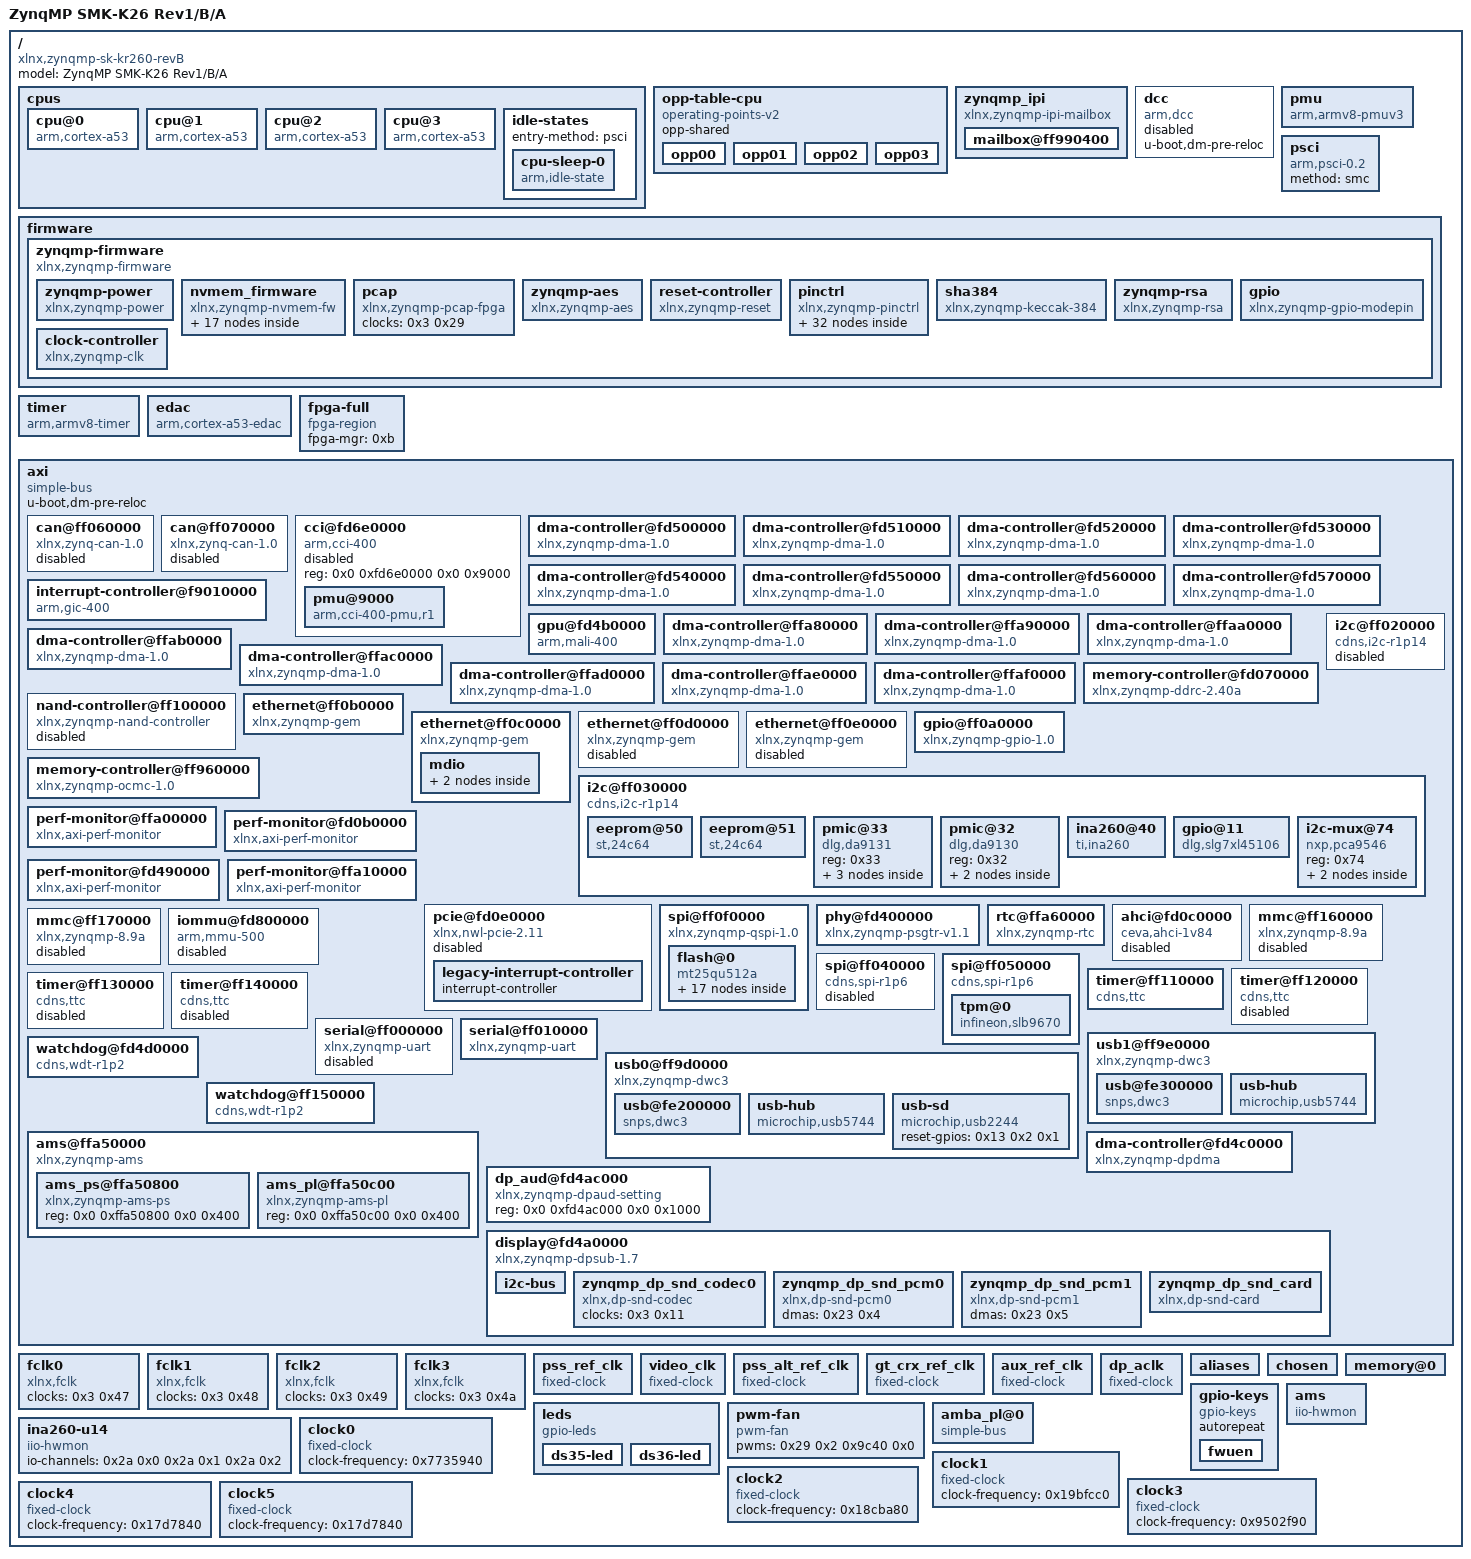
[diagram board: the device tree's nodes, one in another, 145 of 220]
/dts-v1/;

/ {
	compatible = "xlnx,zynqmp-sk-kr260-revB", "xlnx,zynqmp-sk-kr260", "xlnx,zynqmp";
	#address-cells = <0x2>;
	#size-cells = <0x2>;
	model = "ZynqMP SMK-K26 Rev1/B/A";

	cpus {
		#address-cells = <0x1>;
		#size-cells = <0x0>;

		cpu@0 {
			compatible = "arm,cortex-a53";
			device_type = "cpu";
			enable-method = "psci";
			operating-points-v2 = <0x1>;
			reg = <0x0>;
			cpu-idle-states = <0x2>;
			clocks = <0x3 0xa>;
			phandle = <0x2b>;
		};

		cpu@1 {
			compatible = "arm,cortex-a53";
			device_type = "cpu";
			enable-method = "psci";
			reg = <0x1>;
			operating-points-v2 = <0x1>;
			cpu-idle-states = <0x2>;
			phandle = <0x2c>;
		};

		cpu@2 {
			compatible = "arm,cortex-a53";
			device_type = "cpu";
			enable-method = "psci";
			reg = <0x2>;
			operating-points-v2 = <0x1>;
			cpu-idle-states = <0x2>;
			phandle = <0x2d>;
		};

		cpu@3 {
			compatible = "arm,cortex-a53";
			device_type = "cpu";
			enable-method = "psci";
			reg = <0x3>;
			operating-points-v2 = <0x1>;
			cpu-idle-states = <0x2>;
			phandle = <0x2e>;
		};

		idle-states {
			entry-method = "psci";

			cpu-sleep-0 {
				compatible = "arm,idle-state";
				arm,psci-suspend-param = <0x40000000>;
				local-timer-stop;
				entry-latency-us = <0x12c>;
				exit-latency-us = <0x258>;
				min-residency-us = <0x2710>;
				phandle = <0x2>;
			};
		};
	};

	opp-table-cpu {
		compatible = "operating-points-v2";
		opp-shared;
		phandle = <0x1>;

		opp00 {
			opp-hz = <0x0 0x4f790d55>;
			opp-microvolt = <0xf4240>;
			clock-latency-ns = <0x7a120>;
		};

		opp01 {
			opp-hz = <0x0 0x27bc86aa>;
			opp-microvolt = <0xf4240>;
			clock-latency-ns = <0x7a120>;
		};

		opp02 {
			opp-hz = <0x0 0x1a7daf1c>;
			opp-microvolt = <0xf4240>;
			clock-latency-ns = <0x7a120>;
		};

		opp03 {
			opp-hz = <0x0 0x13de4355>;
			opp-microvolt = <0xf4240>;
			clock-latency-ns = <0x7a120>;
		};
	};

	zynqmp_ipi {
		u-boot,dm-pre-reloc;
		compatible = "xlnx,zynqmp-ipi-mailbox";
		interrupt-parent = <0x4>;
		interrupts = <0x0 0x23 0x4>;
		xlnx,ipi-id = <0x0>;
		#address-cells = <0x2>;
		#size-cells = <0x2>;
		ranges;
		phandle = <0x2f>;

		mailbox@ff990400 {
			u-boot,dm-pre-reloc;
			reg = <0x0 0xff9905c0 0x0 0x20 0x0 0xff9905e0 0x0 0x20 0x0 0xff990e80 0x0 0x20 0x0 0xff990ea0 0x0 0x20>;
			reg-names = "local_request_region", "local_response_region", "remote_request_region", "remote_response_region";
			#mbox-cells = <0x1>;
			xlnx,ipi-id = <0x4>;
			phandle = <0x5>;
		};
	};

	dcc {
		compatible = "arm,dcc";
		status = "disabled";
		u-boot,dm-pre-reloc;
		phandle = <0x30>;
	};

	pmu {
		compatible = "arm,armv8-pmuv3";
		interrupt-parent = <0x4>;
		interrupts = <0x0 0x8f 0x4 0x0 0x90 0x4 0x0 0x91 0x4 0x0 0x92 0x4>;
	};

	psci {
		compatible = "arm,psci-0.2";
		method = "smc";
	};

	firmware {

		zynqmp-firmware {
			compatible = "xlnx,zynqmp-firmware";
			#power-domain-cells = <0x1>;
			method = "smc";
			u-boot,dm-pre-reloc;
			phandle = <0xc>;

			zynqmp-power {
				u-boot,dm-pre-reloc;
				compatible = "xlnx,zynqmp-power";
				interrupt-parent = <0x4>;
				interrupts = <0x0 0x23 0x4>;
				mboxes = <0x5 0x0 0x5 0x1>;
				mbox-names = "tx", "rx";
				phandle = <0x31>;
			};

			nvmem_firmware {
				compatible = "xlnx,zynqmp-nvmem-fw";
				#address-cells = <0x1>;
				#size-cells = <0x1>;

				soc_revision@0 {
					reg = <0x0 0x4>;
					phandle = <0x32>;
				};

				efuse_dna@c {
					reg = <0xc 0xc>;
					phandle = <0x33>;
				};

				efuse_usr0@20 {
					reg = <0x20 0x4>;
					phandle = <0x34>;
				};

				efuse_usr1@24 {
					reg = <0x24 0x4>;
					phandle = <0x35>;
				};

				efuse_usr2@28 {
					reg = <0x28 0x4>;
					phandle = <0x36>;
				};

				efuse_usr3@2c {
					reg = <0x2c 0x4>;
					phandle = <0x37>;
				};

				efuse_usr4@30 {
					reg = <0x30 0x4>;
					phandle = <0x38>;
				};

				efuse_usr5@34 {
					reg = <0x34 0x4>;
					phandle = <0x39>;
				};

				efuse_usr6@38 {
					reg = <0x38 0x4>;
					phandle = <0x3a>;
				};

				efuse_usr7@3c {
					reg = <0x3c 0x4>;
					phandle = <0x3b>;
				};

				efuse_miscusr@40 {
					reg = <0x40 0x4>;
					phandle = <0x3c>;
				};

				efuse_chash@50 {
					reg = <0x50 0x4>;
					phandle = <0x3d>;
				};

				efuse_pufmisc@54 {
					reg = <0x54 0x4>;
					phandle = <0x3e>;
				};

				efuse_sec@58 {
					reg = <0x58 0x4>;
					phandle = <0x3f>;
				};

				efuse_spkid@5c {
					reg = <0x5c 0x4>;
					phandle = <0x40>;
				};

				efuse_ppk0hash@a0 {
					reg = <0xa0 0x30>;
					phandle = <0x41>;
				};

				efuse_ppk1hash@d0 {
					reg = <0xd0 0x30>;
					phandle = <0x42>;
				};
			};

			pcap {
				compatible = "xlnx,zynqmp-pcap-fpga";
				clock-names = "ref_clk";
				clocks = <0x3 0x29>;
				phandle = <0xb>;
			};

			zynqmp-aes {
				compatible = "xlnx,zynqmp-aes";
				phandle = <0x43>;
			};

			reset-controller {
				compatible = "xlnx,zynqmp-reset";
				#reset-cells = <0x1>;
				phandle = <0xe>;
			};

			pinctrl {
				compatible = "xlnx,zynqmp-pinctrl";
				status = "okay";
				phandle = <0x44>;

				sdhci0-default {
					phandle = <0x1c>;

					conf {
						groups = "sdio0_0_grp";
						slew-rate = <0x1>;
						power-source = <0x1>;
						bias-disable;
					};

					mux {
						groups = "sdio0_0_grp";
						function = "sdio0";
					};
				};

				uart1-default {
					phandle = <0x1d>;

					conf {
						groups = "uart1_9_grp";
						slew-rate = <0x1>;
						power-source = <0x1>;
						drive-strength = <0xc>;
					};

					conf-rx {
						pins = "MIO37";
						bias-high-impedance;
					};

					conf-tx {
						pins = "MIO36";
						bias-disable;
					};

					mux {
						groups = "uart1_9_grp";
						function = "uart1";
					};
				};

				i2c1-default {
					phandle = <0x15>;

					conf {
						groups = "i2c1_6_grp";
						bias-pull-up;
						slew-rate = <0x1>;
						power-source = <0x1>;
					};

					mux {
						groups = "i2c1_6_grp";
						function = "i2c1";
					};
				};

				i2c1-gpio {
					phandle = <0x16>;

					conf {
						groups = "gpio0_24_grp", "gpio0_25_grp";
						slew-rate = <0x1>;
						power-source = <0x1>;
					};

					mux {
						groups = "gpio0_24_grp", "gpio0_25_grp";
						function = "gpio0";
					};
				};

				gem1-default {
					phandle = <0x11>;

					conf {
						groups = "ethernet1_0_grp";
						slew-rate = <0x1>;
						power-source = <0x1>;
					};

					conf-rx {
						pins = "MIO44", "MIO46", "MIO48";
						bias-high-impedance;
						low-power-disable;
					};

					conf-bootstrap {
						pins = "MIO45", "MIO47", "MIO49";
						bias-disable;
						low-power-disable;
					};

					conf-tx {
						pins = "MIO38", "MIO39", "MIO40", "MIO41", "MIO42", "MIO43";
						bias-disable;
						low-power-enable;
					};

					conf-mdio {
						groups = "mdio1_0_grp";
						slew-rate = <0x1>;
						power-source = <0x1>;
						bias-disable;
					};

					mux-mdio {
						function = "mdio1";
						groups = "mdio1_0_grp";
					};

					mux {
						function = "ethernet1";
						groups = "ethernet1_0_grp";
					};
				};

				usb0-default {
					phandle = <0x1e>;

					conf {
						groups = "usb0_0_grp";
						power-source = <0x1>;
					};

					conf-rx {
						pins = "MIO52", "MIO53", "MIO55";
						bias-high-impedance;
						drive-strength = <0xc>;
						slew-rate = <0x0>;
					};

					conf-tx {
						pins = "MIO54", "MIO56", "MIO57", "MIO58", "MIO59", "MIO60", "MIO61", "MIO62", "MIO63";
						bias-disable;
						drive-strength = <0x4>;
						slew-rate = <0x1>;
					};

					mux {
						groups = "usb0_0_grp";
						function = "usb0";
					};
				};

				usb1-default {
					phandle = <0x20>;

					conf {
						groups = "usb1_0_grp";
						power-source = <0x1>;
					};

					conf-rx {
						pins = "MIO64", "MIO65", "MIO67";
						bias-high-impedance;
						drive-strength = <0xc>;
						slew-rate = <0x0>;
					};

					conf-tx {
						pins = "MIO66", "MIO68", "MIO69", "MIO70", "MIO71", "MIO72", "MIO73", "MIO74", "MIO75";
						bias-disable;
						drive-strength = <0x4>;
						slew-rate = <0x1>;
					};

					mux {
						groups = "usb1_0_grp";
						function = "usb1";
					};
				};
			};

			sha384 {
				compatible = "xlnx,zynqmp-keccak-384";
				phandle = <0x45>;
			};

			zynqmp-rsa {
				compatible = "xlnx,zynqmp-rsa";
				phandle = <0x46>;
			};

			gpio {
				compatible = "xlnx,zynqmp-gpio-modepin";
				gpio-controller;
				#gpio-cells = <0x2>;
				label = "modepin";
				phandle = <0x47>;
			};

			clock-controller {
				u-boot,dm-pre-reloc;
				#clock-cells = <0x1>;
				compatible = "xlnx,zynqmp-clk";
				clocks = <0x6 0x7 0x8 0x9 0xa>;
				clock-names = "pss_ref_clk", "video_clk", "pss_alt_ref_clk", "aux_ref_clk", "gt_crx_ref_clk";
				phandle = <0x3>;
			};
		};
	};

	timer {
		compatible = "arm,armv8-timer";
		interrupt-parent = <0x4>;
		interrupts = <0x1 0xd 0xf08 0x1 0xe 0xf08 0x1 0xb 0xf08 0x1 0xa 0xf08>;
	};

	edac {
		compatible = "arm,cortex-a53-edac";
	};

	fpga-full {
		compatible = "fpga-region";
		fpga-mgr = <0xb>;
		#address-cells = <0x2>;
		#size-cells = <0x2>;
		ranges;
		phandle = <0x48>;
	};

	axi {
		compatible = "simple-bus";
		u-boot,dm-pre-reloc;
		#address-cells = <0x2>;
		#size-cells = <0x2>;
		ranges;
		phandle = <0x49>;

		can@ff060000 {
			compatible = "xlnx,zynq-can-1.0";
			status = "disabled";
			clock-names = "can_clk", "pclk";
			reg = <0x0 0xff060000 0x0 0x1000>;
			interrupts = <0x0 0x17 0x4>;
			interrupt-parent = <0x4>;
			tx-fifo-depth = <0x40>;
			rx-fifo-depth = <0x40>;
			power-domains = <0xc 0x2f>;
			clocks = <0x3 0x3f 0x3 0x1f>;
			phandle = <0x4a>;
		};

		can@ff070000 {
			compatible = "xlnx,zynq-can-1.0";
			status = "disabled";
			clock-names = "can_clk", "pclk";
			reg = <0x0 0xff070000 0x0 0x1000>;
			interrupts = <0x0 0x18 0x4>;
			interrupt-parent = <0x4>;
			tx-fifo-depth = <0x40>;
			rx-fifo-depth = <0x40>;
			power-domains = <0xc 0x30>;
			clocks = <0x3 0x40 0x3 0x1f>;
			phandle = <0x4b>;
		};

		cci@fd6e0000 {
			compatible = "arm,cci-400";
			status = "disabled";
			reg = <0x0 0xfd6e0000 0x0 0x9000>;
			ranges = <0x0 0x0 0xfd6e0000 0x10000>;
			#address-cells = <0x1>;
			#size-cells = <0x1>;
			phandle = <0x4c>;

			pmu@9000 {
				compatible = "arm,cci-400-pmu,r1";
				reg = <0x9000 0x5000>;
				interrupt-parent = <0x4>;
				interrupts = <0x0 0x7b 0x4 0x0 0x7b 0x4 0x0 0x7b 0x4 0x0 0x7b 0x4 0x0 0x7b 0x4>;
			};
		};

		dma-controller@fd500000 {
			status = "okay";
			compatible = "xlnx,zynqmp-dma-1.0";
			reg = <0x0 0xfd500000 0x0 0x1000>;
			interrupt-parent = <0x4>;
			interrupts = <0x0 0x7c 0x4>;
			clock-names = "clk_main", "clk_apb";
			xlnx,bus-width = <0x80>;
			iommus = <0xd 0x14e8>;
			power-domains = <0xc 0x2a>;
			#dma-cells = <0x1>;
			clocks = <0x3 0x13 0x3 0x1f>;
			phandle = <0x4d>;
		};

		dma-controller@fd510000 {
			status = "okay";
			compatible = "xlnx,zynqmp-dma-1.0";
			reg = <0x0 0xfd510000 0x0 0x1000>;
			interrupt-parent = <0x4>;
			interrupts = <0x0 0x7d 0x4>;
			clock-names = "clk_main", "clk_apb";
			xlnx,bus-width = <0x80>;
			iommus = <0xd 0x14e9>;
			power-domains = <0xc 0x2a>;
			#dma-cells = <0x1>;
			clocks = <0x3 0x13 0x3 0x1f>;
			phandle = <0x4e>;
		};

		dma-controller@fd520000 {
			status = "okay";
			compatible = "xlnx,zynqmp-dma-1.0";
			reg = <0x0 0xfd520000 0x0 0x1000>;
			interrupt-parent = <0x4>;
			interrupts = <0x0 0x7e 0x4>;
			clock-names = "clk_main", "clk_apb";
			xlnx,bus-width = <0x80>;
			iommus = <0xd 0x14ea>;
			power-domains = <0xc 0x2a>;
			#dma-cells = <0x1>;
			clocks = <0x3 0x13 0x3 0x1f>;
			phandle = <0x4f>;
		};

		dma-controller@fd530000 {
			status = "okay";
			compatible = "xlnx,zynqmp-dma-1.0";
			reg = <0x0 0xfd530000 0x0 0x1000>;
			interrupt-parent = <0x4>;
			interrupts = <0x0 0x7f 0x4>;
			clock-names = "clk_main", "clk_apb";
			xlnx,bus-width = <0x80>;
			iommus = <0xd 0x14eb>;
			power-domains = <0xc 0x2a>;
			#dma-cells = <0x1>;
			clocks = <0x3 0x13 0x3 0x1f>;
			phandle = <0x50>;
		};

		dma-controller@fd540000 {
			status = "okay";
			compatible = "xlnx,zynqmp-dma-1.0";
			reg = <0x0 0xfd540000 0x0 0x1000>;
			interrupt-parent = <0x4>;
			interrupts = <0x0 0x80 0x4>;
			clock-names = "clk_main", "clk_apb";
			xlnx,bus-width = <0x80>;
			iommus = <0xd 0x14ec>;
			power-domains = <0xc 0x2a>;
			#dma-cells = <0x1>;
			clocks = <0x3 0x13 0x3 0x1f>;
			phandle = <0x51>;
		};

		dma-controller@fd550000 {
			status = "okay";
			compatible = "xlnx,zynqmp-dma-1.0";
			reg = <0x0 0xfd550000 0x0 0x1000>;
			interrupt-parent = <0x4>;
			interrupts = <0x0 0x81 0x4>;
			clock-names = "clk_main", "clk_apb";
			xlnx,bus-width = <0x80>;
			iommus = <0xd 0x14ed>;
			power-domains = <0xc 0x2a>;
			#dma-cells = <0x1>;
			clocks = <0x3 0x13 0x3 0x1f>;
			phandle = <0x52>;
		};

		dma-controller@fd560000 {
			status = "okay";
			compatible = "xlnx,zynqmp-dma-1.0";
			reg = <0x0 0xfd560000 0x0 0x1000>;
			interrupt-parent = <0x4>;
			interrupts = <0x0 0x82 0x4>;
			clock-names = "clk_main", "clk_apb";
			xlnx,bus-width = <0x80>;
			iommus = <0xd 0x14ee>;
			power-domains = <0xc 0x2a>;
			#dma-cells = <0x1>;
			clocks = <0x3 0x13 0x3 0x1f>;
			phandle = <0x53>;
		};

		dma-controller@fd570000 {
			status = "okay";
			compatible = "xlnx,zynqmp-dma-1.0";
			reg = <0x0 0xfd570000 0x0 0x1000>;
			interrupt-parent = <0x4>;
			interrupts = <0x0 0x83 0x4>;
			clock-names = "clk_main", "clk_apb";
			xlnx,bus-width = <0x80>;
			iommus = <0xd 0x14ef>;
			power-domains = <0xc 0x2a>;
			#dma-cells = <0x1>;
			clocks = <0x3 0x13 0x3 0x1f>;
			phandle = <0x54>;
		};

		interrupt-controller@f9010000 {
			compatible = "arm,gic-400";
			#interrupt-cells = <0x3>;
			reg = <0x0 0xf9010000 0x0 0x10000 0x0 0xf9020000 0x0 0x20000 0x0 0xf9040000 0x0 0x20000 0x0 0xf9060000 0x0 0x20000>;
			interrupt-controller;
			interrupt-parent = <0x4>;
			interrupts = <0x1 0x9 0xf04>;
			phandle = <0x4>;
		};

		gpu@fd4b0000 {
			status = "okay";
			compatible = "arm,mali-400", "arm,mali-utgard";
			reg = <0x0 0xfd4b0000 0x0 0x10000>;
			interrupt-parent = <0x4>;
			interrupts = <0x0 0x84 0x4 0x0 0x84 0x4 0x0 0x84 0x4 0x0 0x84 0x4 0x0 0x84 0x4 0x0 0x84 0x4>;
			interrupt-names = "IRQGP", "IRQGPMMU", "IRQPP0", "IRQPPMMU0", "IRQPP1", "IRQPPMMU1";
			clock-names = "gpu", "gpu_pp0", "gpu_pp1";
			power-domains = <0xc 0x3a>;
			clocks = <0x3 0x18 0x3 0x19 0x3 0x1a>;
			phandle = <0x55>;
		};

		dma-controller@ffa80000 {
			status = "okay";
			compatible = "xlnx,zynqmp-dma-1.0";
			reg = <0x0 0xffa80000 0x0 0x1000>;
			interrupt-parent = <0x4>;
			interrupts = <0x0 0x4d 0x4>;
			clock-names = "clk_main", "clk_apb";
			xlnx,bus-width = <0x40>;
			power-domains = <0xc 0x2b>;
			#dma-cells = <0x1>;
			clocks = <0x3 0x44 0x3 0x1f>;
			phandle = <0x56>;
		};

		dma-controller@ffa90000 {
			status = "okay";
			compatible = "xlnx,zynqmp-dma-1.0";
			reg = <0x0 0xffa90000 0x0 0x1000>;
			interrupt-parent = <0x4>;
			interrupts = <0x0 0x4e 0x4>;
			clock-names = "clk_main", "clk_apb";
			xlnx,bus-width = <0x40>;
			power-domains = <0xc 0x2b>;
			#dma-cells = <0x1>;
			clocks = <0x3 0x44 0x3 0x1f>;
			phandle = <0x57>;
		};

		dma-controller@ffaa0000 {
			status = "okay";
			compatible = "xlnx,zynqmp-dma-1.0";
			reg = <0x0 0xffaa0000 0x0 0x1000>;
			interrupt-parent = <0x4>;
			interrupts = <0x0 0x4f 0x4>;
			clock-names = "clk_main", "clk_apb";
			xlnx,bus-width = <0x40>;
			power-domains = <0xc 0x2b>;
			#dma-cells = <0x1>;
			clocks = <0x3 0x44 0x3 0x1f>;
			phandle = <0x58>;
		};

		dma-controller@ffab0000 {
			status = "okay";
			compatible = "xlnx,zynqmp-dma-1.0";
			reg = <0x0 0xffab0000 0x0 0x1000>;
			interrupt-parent = <0x4>;
			interrupts = <0x0 0x50 0x4>;
			clock-names = "clk_main", "clk_apb";
			xlnx,bus-width = <0x40>;
			power-domains = <0xc 0x2b>;
			#dma-cells = <0x1>;
			clocks = <0x3 0x44 0x3 0x1f>;
			phandle = <0x59>;
		};

		dma-controller@ffac0000 {
			status = "okay";
			compatible = "xlnx,zynqmp-dma-1.0";
			reg = <0x0 0xffac0000 0x0 0x1000>;
			interrupt-parent = <0x4>;
			interrupts = <0x0 0x51 0x4>;
			clock-names = "clk_main", "clk_apb";
			xlnx,bus-width = <0x40>;
			power-domains = <0xc 0x2b>;
			#dma-cells = <0x1>;
			clocks = <0x3 0x44 0x3 0x1f>;
			phandle = <0x5a>;
		};

		dma-controller@ffad0000 {
			status = "okay";
			compatible = "xlnx,zynqmp-dma-1.0";
			reg = <0x0 0xffad0000 0x0 0x1000>;
			interrupt-parent = <0x4>;
			interrupts = <0x0 0x52 0x4>;
			clock-names = "clk_main", "clk_apb";
			xlnx,bus-width = <0x40>;
			power-domains = <0xc 0x2b>;
			#dma-cells = <0x1>;
			clocks = <0x3 0x44 0x3 0x1f>;
			phandle = <0x5b>;
		};

		dma-controller@ffae0000 {
			status = "okay";
			compatible = "xlnx,zynqmp-dma-1.0";
			reg = <0x0 0xffae0000 0x0 0x1000>;
			interrupt-parent = <0x4>;
			interrupts = <0x0 0x53 0x4>;
			clock-names = "clk_main", "clk_apb";
			xlnx,bus-width = <0x40>;
			power-domains = <0xc 0x2b>;
			#dma-cells = <0x1>;
			clocks = <0x3 0x44 0x3 0x1f>;
			phandle = <0x5c>;
		};

		dma-controller@ffaf0000 {
			status = "okay";
			compatible = "xlnx,zynqmp-dma-1.0";
			reg = <0x0 0xffaf0000 0x0 0x1000>;
			interrupt-parent = <0x4>;
			interrupts = <0x0 0x54 0x4>;
			clock-names = "clk_main", "clk_apb";
			xlnx,bus-width = <0x40>;
			power-domains = <0xc 0x2b>;
			#dma-cells = <0x1>;
			clocks = <0x3 0x44 0x3 0x1f>;
			phandle = <0x5d>;
		};

		memory-controller@fd070000 {
			compatible = "xlnx,zynqmp-ddrc-2.40a";
			reg = <0x0 0xfd070000 0x0 0x30000>;
			interrupt-parent = <0x4>;
			interrupts = <0x0 0x70 0x4>;
			phandle = <0x5e>;
		};

		nand-controller@ff100000 {
			compatible = "xlnx,zynqmp-nand-controller", "arasan,nfc-v3p10";
			status = "disabled";
			reg = <0x0 0xff100000 0x0 0x1000>;
			clock-names = "controller", "bus";
			interrupt-parent = <0x4>;
			interrupts = <0x0 0xe 0x4>;
			#address-cells = <0x1>;
			#size-cells = <0x0>;
			iommus = <0xd 0x872>;
			power-domains = <0xc 0x2c>;
			clocks = <0x3 0x3c 0x3 0x1f>;
			phandle = <0x5f>;
		};

		ethernet@ff0b0000 {
			compatible = "xlnx,zynqmp-gem", "cdns,zynqmp-gem", "cdns,gem";
			status = "okay";
			interrupt-parent = <0x4>;
			interrupts = <0x0 0x39 0x4 0x0 0x39 0x4>;
			reg = <0x0 0xff0b0000 0x0 0x1000>;
			clock-names = "pclk", "hclk", "tx_clk", "rx_clk", "tsu_clk";
			#address-cells = <0x1>;
			#size-cells = <0x0>;
			iommus = <0xd 0x874>;
			power-domains = <0xc 0x1d>;
			resets = <0xe 0x1d>;
			clocks = <0x3 0x1f 0x3 0x68 0x3 0x2d 0x3 0x31 0x3 0x2c>;
			phys = <0xf 0x0 0x8 0x0 0x0>;
			phy-handle = <0x10>;
			phy-mode = "sgmii";
			is-internal-pcspma;
			phandle = <0x60>;
		};

		ethernet@ff0c0000 {
			compatible = "xlnx,zynqmp-gem", "cdns,zynqmp-gem", "cdns,gem";
			status = "okay";
			interrupt-parent = <0x4>;
			interrupts = <0x0 0x3b 0x4 0x0 0x3b 0x4>;
			reg = <0x0 0xff0c0000 0x0 0x1000>;
			clock-names = "pclk", "hclk", "tx_clk", "rx_clk", "tsu_clk";
			#address-cells = <0x1>;
			#size-cells = <0x0>;
			iommus = <0xd 0x875>;
			power-domains = <0xc 0x1e>;
			resets = <0xe 0x1e>;
			clocks = <0x3 0x1f 0x3 0x69 0x3 0x2e 0x3 0x32 0x3 0x2c>;
			pinctrl-names = "default";
			pinctrl-0 = <0x11>;
			phy-handle = <0x12>;
			phy-mode = "rgmii-id";
			phandle = <0x61>;

			mdio {
				#address-cells = <0x1>;
				#size-cells = <0x0>;
				phandle = <0x62>;

				ethernet-phy@4 {
					#phy-cells = <0x1>;
					compatible = "ethernet-phy-id2000.a231";
					reg = <0x4>;
					ti,rx-internal-delay = <0x8>;
					ti,tx-internal-delay = <0xa>;
					ti,fifo-depth = <0x1>;
					ti,dp83867-rxctrl-strap-quirk;
					reset-assert-us = <0x64>;
					reset-deassert-us = <0x118>;
					reset-gpios = <0x13 0x5 0x1>;
					phandle = <0x10>;
				};

				ethernet-phy@8 {
					#phy-cells = <0x1>;
					compatible = "ethernet-phy-id2000.a231";
					reg = <0x8>;
					ti,rx-internal-delay = <0x8>;
					ti,tx-internal-delay = <0xa>;
					ti,fifo-depth = <0x1>;
					ti,dp83867-rxctrl-strap-quirk;
					reset-assert-us = <0x64>;
					reset-deassert-us = <0x118>;
					reset-gpios = <0x13 0x6 0x1>;
					phandle = <0x12>;
				};
			};
		};

		ethernet@ff0d0000 {
			compatible = "xlnx,zynqmp-gem", "cdns,zynqmp-gem", "cdns,gem";
			status = "disabled";
			interrupt-parent = <0x4>;
			interrupts = <0x0 0x3d 0x4 0x0 0x3d 0x4>;
			reg = <0x0 0xff0d0000 0x0 0x1000>;
			clock-names = "pclk", "hclk", "tx_clk", "rx_clk", "tsu_clk";
			#address-cells = <0x1>;
			#size-cells = <0x0>;
			iommus = <0xd 0x876>;
			power-domains = <0xc 0x1f>;
			resets = <0xe 0x1f>;
			clocks = <0x3 0x1f 0x3 0x6a 0x3 0x2f 0x3 0x33 0x3 0x2c>;
			phandle = <0x63>;
		};

		ethernet@ff0e0000 {
			compatible = "xlnx,zynqmp-gem", "cdns,zynqmp-gem", "cdns,gem";
			status = "disabled";
			interrupt-parent = <0x4>;
			interrupts = <0x0 0x3f 0x4 0x0 0x3f 0x4>;
			reg = <0x0 0xff0e0000 0x0 0x1000>;
			clock-names = "pclk", "hclk", "tx_clk", "rx_clk", "tsu_clk";
			#address-cells = <0x1>;
			#size-cells = <0x0>;
			iommus = <0xd 0x877>;
			power-domains = <0xc 0x20>;
			resets = <0xe 0x20>;
			clocks = <0x3 0x1f 0x3 0x6b 0x3 0x30 0x3 0x34 0x3 0x2c>;
			phandle = <0x64>;
		};

		gpio@ff0a0000 {
			compatible = "xlnx,zynqmp-gpio-1.0";
			status = "okay";
			#gpio-cells = <0x2>;
			gpio-controller;
			interrupt-parent = <0x4>;
			interrupts = <0x0 0x10 0x4>;
			interrupt-controller;
			#interrupt-cells = <0x2>;
			reg = <0x0 0xff0a0000 0x0 0x1000>;
			power-domains = <0xc 0x2e>;
			clocks = <0x3 0x1f>;
			gpio-line-names = "QSPI_CLK", "QSPI_DQ1", "QSPI_DQ2", "QSPI_DQ3", "QSPI_DQ0", "QSPI_CS_B", "SPI_CLK", "LED1", "LED2", "SPI_CS_B", "SPI_MISO", "SPI_MOSI", "FWUEN", "EMMC_DAT0", "EMMC_DAT1", "EMMC_DAT2", "EMMC_DAT3", "EMMC_DAT4", "EMMC_DAT5", "EMMC_DAT6", "EMMC_DAT7", "EMMC_CMD", "EMMC_CLK", "EMMC_RST", "I2C1_SCL", "I2C1_SDA", "", "", "", "", "", "", "", "", "", "", "", "", "", "", "", "", "", "", "", "", "", "", "", "", "", "", "", "", "", "", "", "", "", "", "", "", "", "", "", "", "", "", "", "", "", "", "", "", "", "", "", "", "", "", "", "", "", "", "", "", "", "", "", "", "", "", "", "", "", "", "", "", "", "", "", "", "", "", "", "", "", "", "", "", "", "", "", "", "", "", "", "", "", "", "", "", "", "", "", "", "", "", "", "", "", "", "", "", "", "", "", "", "", "", "", "", "", "", "", "", "", "", "", "", "", "", "", "", "", "", "", "", "", "", "", "", "", "", "", "", "", "", "", "", "", "", "", "";
			phandle = <0x14>;
		};

		i2c@ff020000 {
			compatible = "cdns,i2c-r1p14";
			status = "disabled";
			interrupt-parent = <0x4>;
			interrupts = <0x0 0x11 0x4>;
			reg = <0x0 0xff020000 0x0 0x1000>;
			#address-cells = <0x1>;
			#size-cells = <0x0>;
			power-domains = <0xc 0x25>;
			clocks = <0x3 0x3d>;
			phandle = <0x65>;
		};

		i2c@ff030000 {
			compatible = "cdns,i2c-r1p14";
			status = "okay";
			interrupt-parent = <0x4>;
			interrupts = <0x0 0x12 0x4>;
			reg = <0x0 0xff030000 0x0 0x1000>;
			#address-cells = <0x1>;
			#size-cells = <0x0>;
			power-domains = <0xc 0x26>;
			clocks = <0x3 0x3e>;
			u-boot,dm-pre-reloc;
			clock-frequency = <0x61a80>;
			scl-gpios = <0x14 0x18 0x0>;
			sda-gpios = <0x14 0x19 0x0>;
			pinctrl-names = "default", "gpio";
			pinctrl-0 = <0x15>;
			pinctrl-1 = <0x16>;
			phandle = <0x66>;

			eeprom@50 {
				u-boot,dm-pre-reloc;
				compatible = "st,24c64", "atmel,24c64";
				reg = <0x50>;
				phandle = <0x67>;
			};

			eeprom@51 {
				u-boot,dm-pre-reloc;
				compatible = "st,24c64", "atmel,24c64";
				reg = <0x51>;
				phandle = <0x68>;
			};

			pmic@33 {
				compatible = "dlg,da9131";
				reg = <0x33>;
				phandle = <0x69>;

				regulators {

					buck1 {
						regulator-name = "da9131_buck1";
						regulator-boot-on;
						regulator-always-on;
						phandle = <0x6a>;
					};

					buck2 {
						regulator-name = "da9131_buck2";
						regulator-boot-on;
						regulator-always-on;
						phandle = <0x6b>;
					};
				};
			};

			pmic@32 {
				compatible = "dlg,da9130";
				reg = <0x32>;
				phandle = <0x6c>;

				regulators {

					buck1 {
						regulator-name = "da9130_buck1";
						regulator-boot-on;
						regulator-always-on;
						phandle = <0x6d>;
					};
				};
			};

			ina260@40 {
				compatible = "ti,ina260";
				#io-channel-cells = <0x1>;
				label = "ina260-u14";
				reg = <0x40>;
				phandle = <0x2a>;
			};

			gpio@11 {
				compatible = "dlg,slg7xl45106";
				reg = <0x11>;
				label = "resetchip";
				gpio-controller;
				#gpio-cells = <0x2>;
				gpio-line-names = "USB0_PHY_RESET_B", "USB1_PHY_RESET_B", "SD_RESET_B", "USB0_HUB_RESET_B", "USB1_HUB_RESET_B", "PS_GEM0_RESET_B", "PS_GEM1_RESET_B", "";
				phandle = <0x13>;
			};

			i2c-mux@74 {
				compatible = "nxp,pca9546";
				#address-cells = <0x1>;
				#size-cells = <0x0>;
				reg = <0x74>;

				i2c@0 {
					#address-cells = <0x1>;
					#size-cells = <0x0>;
					reg = <0x0>;
					phandle = <0x1f>;
				};

				i2c@1 {
					#address-cells = <0x1>;
					#size-cells = <0x0>;
					reg = <0x1>;
					phandle = <0x21>;
				};
			};
		};

		memory-controller@ff960000 {
			compatible = "xlnx,zynqmp-ocmc-1.0";
			reg = <0x0 0xff960000 0x0 0x1000>;
			interrupt-parent = <0x4>;
			interrupts = <0x0 0xa 0x4>;
			phandle = <0x6e>;
		};

		perf-monitor@ffa00000 {
			compatible = "xlnx,axi-perf-monitor";
			reg = <0x0 0xffa00000 0x0 0x10000>;
			interrupts = <0x0 0x19 0x4>;
			interrupt-parent = <0x4>;
			xlnx,enable-profile = <0x0>;
			xlnx,enable-trace = <0x0>;
			xlnx,num-monitor-slots = <0x1>;
			xlnx,enable-event-count = <0x1>;
			xlnx,enable-event-log = <0x1>;
			xlnx,have-sampled-metric-cnt = <0x1>;
			xlnx,num-of-counters = <0x8>;
			xlnx,metric-count-width = <0x20>;
			xlnx,metrics-sample-count-width = <0x20>;
			xlnx,global-count-width = <0x20>;
			xlnx,metric-count-scale = <0x1>;
			clocks = <0x3 0x1f>;
			phandle = <0x6f>;
		};

		perf-monitor@fd0b0000 {
			compatible = "xlnx,axi-perf-monitor";
			reg = <0x0 0xfd0b0000 0x0 0x10000>;
			interrupts = <0x0 0x7b 0x4>;
			interrupt-parent = <0x4>;
			xlnx,enable-profile = <0x0>;
			xlnx,enable-trace = <0x0>;
			xlnx,num-monitor-slots = <0x6>;
			xlnx,enable-event-count = <0x1>;
			xlnx,enable-event-log = <0x0>;
			xlnx,have-sampled-metric-cnt = <0x1>;
			xlnx,num-of-counters = <0xa>;
			xlnx,metric-count-width = <0x20>;
			xlnx,metrics-sample-count-width = <0x20>;
			xlnx,global-count-width = <0x20>;
			xlnx,metric-count-scale = <0x1>;
			clocks = <0x3 0x1c>;
			phandle = <0x70>;
		};

		perf-monitor@fd490000 {
			compatible = "xlnx,axi-perf-monitor";
			reg = <0x0 0xfd490000 0x0 0x10000>;
			interrupts = <0x0 0x7b 0x4>;
			interrupt-parent = <0x4>;
			xlnx,enable-profile = <0x0>;
			xlnx,enable-trace = <0x0>;
			xlnx,num-monitor-slots = <0x1>;
			xlnx,enable-event-count = <0x1>;
			xlnx,enable-event-log = <0x0>;
			xlnx,have-sampled-metric-cnt = <0x1>;
			xlnx,num-of-counters = <0x8>;
			xlnx,metric-count-width = <0x20>;
			xlnx,metrics-sample-count-width = <0x20>;
			xlnx,global-count-width = <0x20>;
			xlnx,metric-count-scale = <0x1>;
			clocks = <0x3 0x1c>;
			phandle = <0x71>;
		};

		perf-monitor@ffa10000 {
			compatible = "xlnx,axi-perf-monitor";
			reg = <0x0 0xffa10000 0x0 0x10000>;
			interrupts = <0x0 0x19 0x4>;
			interrupt-parent = <0x4>;
			xlnx,enable-profile = <0x0>;
			xlnx,enable-trace = <0x0>;
			xlnx,num-monitor-slots = <0x1>;
			xlnx,enable-event-count = <0x1>;
			xlnx,enable-event-log = <0x1>;
			xlnx,have-sampled-metric-cnt = <0x1>;
			xlnx,num-of-counters = <0x8>;
			xlnx,metric-count-width = <0x20>;
			xlnx,metrics-sample-count-width = <0x20>;
			xlnx,global-count-width = <0x20>;
			xlnx,metric-count-scale = <0x1>;
			clocks = <0x3 0x1f>;
			phandle = <0x72>;
		};

		pcie@fd0e0000 {
			compatible = "xlnx,nwl-pcie-2.11";
			status = "disabled";
			#address-cells = <0x3>;
			#size-cells = <0x2>;
			#interrupt-cells = <0x1>;
			msi-controller;
			device_type = "pci";
			interrupt-parent = <0x4>;
			interrupts = <0x0 0x76 0x4 0x0 0x75 0x4 0x0 0x74 0x4 0x0 0x73 0x4 0x0 0x72 0x4>;
			interrupt-names = "misc", "dummy", "intx", "msi1", "msi0";
			msi-parent = <0x17>;
			reg = <0x0 0xfd0e0000 0x0 0x1000 0x0 0xfd480000 0x0 0x1000 0x80 0x0 0x0 0x1000000>;
			reg-names = "breg", "pcireg", "cfg";
			ranges = <0x2000000 0x0 0xe0000000 0x0 0xe0000000 0x0 0x10000000 0x43000000 0x6 0x0 0x6 0x0 0x2 0x0>;
			bus-range = <0x0 0xff>;
			interrupt-map-mask = <0x0 0x0 0x0 0x7>;
			interrupt-map = <0x0 0x0 0x0 0x1 0x18 0x1 0x0 0x0 0x0 0x2 0x18 0x2 0x0 0x0 0x0 0x3 0x18 0x3 0x0 0x0 0x0 0x4 0x18 0x4>;
			iommus = <0xd 0x4d0>;
			power-domains = <0xc 0x3b>;
			clocks = <0x3 0x17>;
			phandle = <0x17>;

			legacy-interrupt-controller {
				interrupt-controller;
				#address-cells = <0x0>;
				#interrupt-cells = <0x1>;
				phandle = <0x18>;
			};
		};

		spi@ff0f0000 {
			u-boot,dm-pre-reloc;
			compatible = "xlnx,zynqmp-qspi-1.0";
			status = "okay";
			clock-names = "ref_clk", "pclk";
			interrupts = <0x0 0xf 0x4>;
			interrupt-parent = <0x4>;
			num-cs = <0x1>;
			reg = <0x0 0xff0f0000 0x0 0x1000 0x0 0xc0000000 0x0 0x8000000>;
			#address-cells = <0x1>;
			#size-cells = <0x0>;
			iommus = <0xd 0x873>;
			power-domains = <0xc 0x2d>;
			clocks = <0x3 0x35 0x3 0x1f>;
			phandle = <0x73>;

			flash@0 {
				compatible = "mt25qu512a", "jedec,spi-nor";
				#address-cells = <0x1>;
				#size-cells = <0x1>;
				reg = <0x0>;
				spi-tx-bus-width = <0x4>;
				spi-rx-bus-width = <0x4>;
				spi-max-frequency = <0x2625a00>;

				partition@0 {
					label = "Image Selector";
					reg = <0x0 0x80000>;
					read-only;
					lock;
				};

				partition@80000 {
					label = "Image Selector Golden";
					reg = <0x80000 0x80000>;
					read-only;
					lock;
				};

				partition@100000 {
					label = "Persistent Register";
					reg = <0x100000 0x20000>;
				};

				partition@120000 {
					label = "Persistent Register Backup";
					reg = <0x120000 0x20000>;
				};

				partition@140000 {
					label = "Open_1";
					reg = <0x140000 0xc0000>;
				};

				partition@200000 {
					label = "Image A (FSBL, PMU, ATF, U-Boot)";
					reg = <0x200000 0xd00000>;
				};

				partition@f00000 {
					label = "ImgSel Image A Catch";
					reg = <0xf00000 0x80000>;
					read-only;
					lock;
				};

				partition@f80000 {
					label = "Image B (FSBL, PMU, ATF, U-Boot)";
					reg = <0xf80000 0xd00000>;
				};

				partition@1c80000 {
					label = "ImgSel Image B Catch";
					reg = <0x1c80000 0x80000>;
					read-only;
					lock;
				};

				partition@1d00000 {
					label = "Open_2";
					reg = <0x1d00000 0x100000>;
				};

				partition@1e00000 {
					label = "Recovery Image";
					reg = <0x1e00000 0x200000>;
					read-only;
					lock;
				};

				partition@2000000 {
					label = "Recovery Image Backup";
					reg = <0x2000000 0x200000>;
					read-only;
					lock;
				};

				partition@2200000 {
					label = "U-Boot storage variables";
					reg = <0x2200000 0x20000>;
				};

				partition@2220000 {
					label = "U-Boot storage variables backup";
					reg = <0x2220000 0x20000>;
				};

				partition@2240000 {
					label = "SHA256";
					reg = <0x2240000 0x40000>;
					read-only;
					lock;
				};

				partition@2280000 {
					label = "Secure OS Storage";
					reg = <0x2280000 0x20000>;
				};

				partition@22A0000 {
					label = "User";
					reg = <0x22a0000 0x1db0000>;
				};
			};
		};

		phy@fd400000 {
			compatible = "xlnx,zynqmp-psgtr-v1.1";
			status = "okay";
			reg = <0x0 0xfd400000 0x0 0x40000 0x0 0xfd3d0000 0x0 0x1000>;
			reg-names = "serdes", "siou";
			#phy-cells = <0x4>;
			clocks = <0x19 0x1a 0x1b>;
			clock-names = "ref0", "ref1", "ref2";
			phandle = <0xf>;
		};

		rtc@ffa60000 {
			compatible = "xlnx,zynqmp-rtc";
			status = "okay";
			reg = <0x0 0xffa60000 0x0 0x100>;
			interrupt-parent = <0x4>;
			interrupts = <0x0 0x1a 0x4 0x0 0x1b 0x4>;
			interrupt-names = "alarm", "sec";
			calibration = <0x7fff>;
			phandle = <0x74>;
		};

		ahci@fd0c0000 {
			compatible = "ceva,ahci-1v84";
			status = "disabled";
			reg = <0x0 0xfd0c0000 0x0 0x2000>;
			interrupt-parent = <0x4>;
			interrupts = <0x0 0x85 0x4>;
			power-domains = <0xc 0x1c>;
			resets = <0xe 0x10>;
			clocks = <0x3 0x16>;
			phandle = <0x75>;
		};

		mmc@ff160000 {
			u-boot,dm-pre-reloc;
			compatible = "xlnx,zynqmp-8.9a", "arasan,sdhci-8.9a";
			status = "disabled";
			interrupt-parent = <0x4>;
			interrupts = <0x0 0x30 0x4>;
			reg = <0x0 0xff160000 0x0 0x1000>;
			clock-names = "clk_xin", "clk_ahb";
			xlnx,device_id = <0x0>;
			iommus = <0xd 0x870>;
			#clock-cells = <0x1>;
			clock-output-names = "clk_out_sd0", "clk_in_sd0";
			power-domains = <0xc 0x27>;
			resets = <0xe 0x26>;
			clocks = <0x3 0x36 0x3 0x1f>;
			assigned-clocks = <0x3 0x36>;
			pinctrl-names = "default";
			pinctrl-0 = <0x1c>;
			non-removable;
			disable-wp;
			bus-width = <0x8>;
			xlnx,mio-bank = <0x0>;
			assigned-clock-rates = <0xb2cfe8b>;
			phandle = <0x76>;
		};

		mmc@ff170000 {
			u-boot,dm-pre-reloc;
			compatible = "xlnx,zynqmp-8.9a", "arasan,sdhci-8.9a";
			status = "disabled";
			interrupt-parent = <0x4>;
			interrupts = <0x0 0x31 0x4>;
			reg = <0x0 0xff170000 0x0 0x1000>;
			clock-names = "clk_xin", "clk_ahb";
			xlnx,device_id = <0x1>;
			iommus = <0xd 0x871>;
			#clock-cells = <0x1>;
			clock-output-names = "clk_out_sd1", "clk_in_sd1";
			power-domains = <0xc 0x28>;
			resets = <0xe 0x27>;
			clocks = <0x3 0x37 0x3 0x1f>;
			assigned-clocks = <0x3 0x37>;
			phandle = <0x77>;
		};

		iommu@fd800000 {
			compatible = "arm,mmu-500";
			reg = <0x0 0xfd800000 0x0 0x20000>;
			#iommu-cells = <0x1>;
			status = "disabled";
			#global-interrupts = <0x1>;
			interrupt-parent = <0x4>;
			interrupts = <0x0 0x9b 0x4 0x0 0x9b 0x4 0x0 0x9b 0x4 0x0 0x9b 0x4 0x0 0x9b 0x4 0x0 0x9b 0x4 0x0 0x9b 0x4 0x0 0x9b 0x4 0x0 0x9b 0x4 0x0 0x9b 0x4 0x0 0x9b 0x4 0x0 0x9b 0x4 0x0 0x9b 0x4 0x0 0x9b 0x4 0x0 0x9b 0x4 0x0 0x9b 0x4 0x0 0x9b 0x4>;
			phandle = <0xd>;
		};

		spi@ff040000 {
			compatible = "cdns,spi-r1p6";
			status = "disabled";
			interrupt-parent = <0x4>;
			interrupts = <0x0 0x13 0x4>;
			reg = <0x0 0xff040000 0x0 0x1000>;
			clock-names = "ref_clk", "pclk";
			#address-cells = <0x1>;
			#size-cells = <0x0>;
			power-domains = <0xc 0x23>;
			clocks = <0x3 0x3a 0x3 0x1f>;
			phandle = <0x78>;
		};

		spi@ff050000 {
			compatible = "cdns,spi-r1p6";
			status = "okay";
			interrupt-parent = <0x4>;
			interrupts = <0x0 0x14 0x4>;
			reg = <0x0 0xff050000 0x0 0x1000>;
			clock-names = "ref_clk", "pclk";
			#address-cells = <0x1>;
			#size-cells = <0x0>;
			power-domains = <0xc 0x24>;
			clocks = <0x3 0x3b 0x3 0x1f>;
			label = "TPM";
			num-cs = <0x1>;
			phandle = <0x79>;

			tpm@0 {
				compatible = "infineon,slb9670", "tcg,tpm_tis-spi";
				reg = <0x0>;
				spi-max-frequency = <0x11a49a0>;
			};
		};

		timer@ff110000 {
			compatible = "cdns,ttc";
			status = "okay";
			interrupt-parent = <0x4>;
			interrupts = <0x0 0x24 0x4 0x0 0x25 0x4 0x0 0x26 0x4>;
			reg = <0x0 0xff110000 0x0 0x1000>;
			timer-width = <0x20>;
			power-domains = <0xc 0x18>;
			clocks = <0x3 0x1f>;
			#pwm-cells = <0x3>;
			phandle = <0x29>;
		};

		timer@ff120000 {
			compatible = "cdns,ttc";
			status = "disabled";
			interrupt-parent = <0x4>;
			interrupts = <0x0 0x27 0x4 0x0 0x28 0x4 0x0 0x29 0x4>;
			reg = <0x0 0xff120000 0x0 0x1000>;
			timer-width = <0x20>;
			power-domains = <0xc 0x19>;
			clocks = <0x3 0x1f>;
			phandle = <0x7a>;
		};

		timer@ff130000 {
			compatible = "cdns,ttc";
			status = "disabled";
			interrupt-parent = <0x4>;
			interrupts = <0x0 0x2a 0x4 0x0 0x2b 0x4 0x0 0x2c 0x4>;
			reg = <0x0 0xff130000 0x0 0x1000>;
			timer-width = <0x20>;
			power-domains = <0xc 0x1a>;
			clocks = <0x3 0x1f>;
			phandle = <0x7b>;
		};

		timer@ff140000 {
			compatible = "cdns,ttc";
			status = "disabled";
			interrupt-parent = <0x4>;
			interrupts = <0x0 0x2d 0x4 0x0 0x2e 0x4 0x0 0x2f 0x4>;
			reg = <0x0 0xff140000 0x0 0x1000>;
			timer-width = <0x20>;
			power-domains = <0xc 0x1b>;
			clocks = <0x3 0x1f>;
			phandle = <0x7c>;
		};

		serial@ff000000 {
			u-boot,dm-pre-reloc;
			compatible = "xlnx,zynqmp-uart", "cdns,uart-r1p12";
			status = "disabled";
			interrupt-parent = <0x4>;
			interrupts = <0x0 0x15 0x4>;
			reg = <0x0 0xff000000 0x0 0x1000>;
			clock-names = "uart_clk", "pclk";
			power-domains = <0xc 0x21>;
			clocks = <0x3 0x38 0x3 0x1f>;
			phandle = <0x7d>;
		};

		serial@ff010000 {
			u-boot,dm-pre-reloc;
			compatible = "xlnx,zynqmp-uart", "cdns,uart-r1p12";
			status = "okay";
			interrupt-parent = <0x4>;
			interrupts = <0x0 0x16 0x4>;
			reg = <0x0 0xff010000 0x0 0x1000>;
			clock-names = "uart_clk", "pclk";
			power-domains = <0xc 0x22>;
			clocks = <0x3 0x39 0x3 0x1f>;
			pinctrl-names = "default";
			pinctrl-0 = <0x1d>;
			phandle = <0x7e>;
		};

		usb0@ff9d0000 {
			#address-cells = <0x2>;
			#size-cells = <0x2>;
			status = "okay";
			compatible = "xlnx,zynqmp-dwc3";
			reg = <0x0 0xff9d0000 0x0 0x100>;
			clock-names = "bus_clk", "ref_clk";
			power-domains = <0xc 0x16>;
			resets = <0xe 0x3b 0xe 0x3d 0xe 0x3f>;
			reset-names = "usb_crst", "usb_hibrst", "usb_apbrst";
			reset-gpios = <0x13 0x0 0x1>;
			ranges;
			clocks = <0x3 0x20 0x3 0x22>;
			assigned-clocks = <0x3 0x20 0x3 0x22>;
			pinctrl-names = "default";
			pinctrl-0 = <0x1e>;
			phy-names = "usb3-phy";
			phys = <0xf 0x2 0x4 0x0 0x2>;
			assigned-clock-rates = <0xee6b280 0x1312d00>;
			phandle = <0x7f>;

			usb@fe200000 {
				compatible = "snps,dwc3";
				status = "okay";
				reg = <0x0 0xfe200000 0x0 0x40000>;
				interrupt-parent = <0x4>;
				interrupt-names = "dwc_usb3", "otg", "hiber";
				interrupts = <0x0 0x41 0x4 0x0 0x45 0x4 0x0 0x4b 0x4>;
				iommus = <0xd 0x860>;
				snps,quirk-frame-length-adjustment = <0x20>;
				snps,refclk_fladj;
				clock-names = "ref";
				snps,enable_guctl1_resume_quirk;
				snps,enable_guctl1_ipd_quirk;
				snps,xhci-reset-on-resume;
				snps,xhci-stream-quirk;
				clocks = <0x3 0x22>;
				dr_mode = "host";
				snps,usb3_lpm_capable;
				maximum-speed = "super-speed";
				phandle = <0x80>;
			};

			usb-hub {
				i2c-bus = <0x1f>;
				compatible = "microchip,usb5744";
				reset-gpios = <0x13 0x3 0x1>;
				phandle = <0x81>;
			};

			usb-sd {
				compatible = "microchip,usb2244";
				reset-gpios = <0x13 0x2 0x1>;
				phandle = <0x82>;
			};
		};

		usb1@ff9e0000 {
			#address-cells = <0x2>;
			#size-cells = <0x2>;
			status = "okay";
			compatible = "xlnx,zynqmp-dwc3";
			reg = <0x0 0xff9e0000 0x0 0x100>;
			clock-names = "bus_clk", "ref_clk";
			power-domains = <0xc 0x17>;
			resets = <0xe 0x3c 0xe 0x3e 0xe 0x40>;
			reset-names = "usb_crst", "usb_hibrst", "usb_apbrst";
			ranges;
			clocks = <0x3 0x21 0x3 0x22>;
			assigned-clocks = <0x3 0x21 0x3 0x22>;
			pinctrl-names = "default";
			pinctrl-0 = <0x20>;
			phy-names = "usb3-phy";
			phys = <0xf 0x3 0x4 0x1 0x2>;
			reset-gpios = <0x13 0x1 0x1>;
			assigned-clock-rates = <0xee6b280 0x1312d00>;
			phandle = <0x83>;

			usb@fe300000 {
				compatible = "snps,dwc3";
				status = "okay";
				reg = <0x0 0xfe300000 0x0 0x40000>;
				interrupt-parent = <0x4>;
				interrupt-names = "dwc_usb3", "otg", "hiber";
				interrupts = <0x0 0x46 0x4 0x0 0x4a 0x4 0x0 0x4c 0x4>;
				iommus = <0xd 0x861>;
				snps,quirk-frame-length-adjustment = <0x20>;
				snps,refclk_fladj;
				clock-names = "ref";
				snps,enable_guctl1_resume_quirk;
				snps,enable_guctl1_ipd_quirk;
				snps,xhci-reset-on-resume;
				snps,xhci-stream-quirk;
				clocks = <0x3 0x22>;
				dr_mode = "host";
				snps,usb3_lpm_capable;
				maximum-speed = "super-speed";
				phandle = <0x84>;
			};

			usb-hub {
				i2c-bus = <0x21>;
				compatible = "microchip,usb5744";
				reset-gpios = <0x13 0x4 0x1>;
				phandle = <0x85>;
			};
		};

		watchdog@fd4d0000 {
			compatible = "cdns,wdt-r1p2";
			status = "okay";
			interrupt-parent = <0x4>;
			interrupts = <0x0 0x71 0x1>;
			reg = <0x0 0xfd4d0000 0x0 0x1000>;
			timeout-sec = <0x3c>;
			reset-on-timeout;
			clocks = <0x3 0x4b>;
			phandle = <0x86>;
		};

		watchdog@ff150000 {
			compatible = "cdns,wdt-r1p2";
			status = "okay";
			interrupt-parent = <0x4>;
			interrupts = <0x0 0x34 0x1>;
			reg = <0x0 0xff150000 0x0 0x1000>;
			timeout-sec = <0xa>;
			clocks = <0x3 0x70>;
			phandle = <0x87>;
		};

		ams@ffa50000 {
			compatible = "xlnx,zynqmp-ams";
			status = "okay";
			interrupt-parent = <0x4>;
			interrupts = <0x0 0x38 0x4>;
			interrupt-names = "ams-irq";
			reg = <0x0 0xffa50000 0x0 0x800>;
			reg-names = "ams-base";
			#address-cells = <0x2>;
			#size-cells = <0x2>;
			#io-channel-cells = <0x1>;
			ranges;
			clocks = <0x3 0x46>;
			phandle = <0x28>;

			ams_ps@ffa50800 {
				compatible = "xlnx,zynqmp-ams-ps";
				status = "okay";
				reg = <0x0 0xffa50800 0x0 0x400>;
				phandle = <0x88>;
			};

			ams_pl@ffa50c00 {
				compatible = "xlnx,zynqmp-ams-pl";
				status = "okay";
				reg = <0x0 0xffa50c00 0x0 0x400>;
				phandle = <0x89>;
			};
		};

		dma-controller@fd4c0000 {
			compatible = "xlnx,zynqmp-dpdma";
			status = "okay";
			reg = <0x0 0xfd4c0000 0x0 0x1000>;
			interrupts = <0x0 0x7a 0x4>;
			interrupt-parent = <0x4>;
			clock-names = "axi_clk";
			power-domains = <0xc 0x29>;
			dma-channels = <0x6>;
			iommus = <0xd 0xce4>;
			#dma-cells = <0x1>;
			clocks = <0x3 0x14>;
			assigned-clocks = <0x3 0x14>;
			assigned-clock-rates = <0x23c34600>;
			phandle = <0x23>;
		};

		dp_aud@fd4ac000 {
			compatible = "xlnx,zynqmp-dpaud-setting", "syscon";
			reg = <0x0 0xfd4ac000 0x0 0x1000>;
			phandle = <0x22>;
		};

		display@fd4a0000 {
			u-boot,dm-pre-reloc;
			compatible = "xlnx,zynqmp-dpsub-1.7";
			status = "okay";
			reg = <0x0 0xfd4a0000 0x0 0x1000 0x0 0xfd4aa000 0x0 0x1000 0x0 0xfd4ab000 0x0 0x1000>;
			reg-names = "dp", "blend", "av_buf";
			xlnx,dpaud-reg = <0x22>;
			interrupts = <0x0 0x77 0x4>;
			interrupt-parent = <0x4>;
			iommus = <0xd 0xce3>;
			clock-names = "dp_apb_clk", "dp_aud_clk", "dp_vtc_pixel_clk_in";
			power-domains = <0xc 0x29>;
			resets = <0xe 0x3>;
			dma-names = "vid0", "vid1", "vid2", "gfx0";
			dmas = <0x23 0x0 0x23 0x1 0x23 0x2 0x23 0x3>;
			clocks = <0x24 0x3 0x11 0x3 0x10>;
			assigned-clocks = <0x3 0x12 0x3 0x11 0x3 0x10>;
			phy-names = "dp-phy0";
			phys = <0xf 0x1 0x6 0x0 0x1>;
			assigned-clock-rates = <0x19bfcc0 0x17d7840 0x11e1a300>;
			phandle = <0x8a>;

			i2c-bus {
			};

			zynqmp_dp_snd_codec0 {
				compatible = "xlnx,dp-snd-codec";
				clock-names = "aud_clk";
				clocks = <0x3 0x11>;
				phandle = <0x27>;
			};

			zynqmp_dp_snd_pcm0 {
				compatible = "xlnx,dp-snd-pcm0";
				dmas = <0x23 0x4>;
				dma-names = "tx";
				phandle = <0x25>;
			};

			zynqmp_dp_snd_pcm1 {
				compatible = "xlnx,dp-snd-pcm1";
				dmas = <0x23 0x5>;
				dma-names = "tx";
				phandle = <0x26>;
			};

			zynqmp_dp_snd_card {
				compatible = "xlnx,dp-snd-card";
				xlnx,dp-snd-pcm = <0x25 0x26>;
				xlnx,dp-snd-codec = <0x27>;
				phandle = <0x8b>;
			};
		};
	};

	fclk0 {
		status = "okay";
		compatible = "xlnx,fclk";
		clocks = <0x3 0x47>;
		phandle = <0x8c>;
	};

	fclk1 {
		status = "okay";
		compatible = "xlnx,fclk";
		clocks = <0x3 0x48>;
		phandle = <0x8d>;
	};

	fclk2 {
		status = "okay";
		compatible = "xlnx,fclk";
		clocks = <0x3 0x49>;
		phandle = <0x8e>;
	};

	fclk3 {
		status = "okay";
		compatible = "xlnx,fclk";
		clocks = <0x3 0x4a>;
		phandle = <0x8f>;
	};

	pss_ref_clk {
		u-boot,dm-pre-reloc;
		compatible = "fixed-clock";
		#clock-cells = <0x0>;
		clock-frequency = <0x1fca055>;
		phandle = <0x6>;
	};

	video_clk {
		u-boot,dm-pre-reloc;
		compatible = "fixed-clock";
		#clock-cells = <0x0>;
		clock-frequency = <0x19bfcc0>;
		phandle = <0x7>;
	};

	pss_alt_ref_clk {
		u-boot,dm-pre-reloc;
		compatible = "fixed-clock";
		#clock-cells = <0x0>;
		clock-frequency = <0x0>;
		phandle = <0x8>;
	};

	gt_crx_ref_clk {
		u-boot,dm-pre-reloc;
		compatible = "fixed-clock";
		#clock-cells = <0x0>;
		clock-frequency = <0x66ff300>;
		phandle = <0xa>;
	};

	aux_ref_clk {
		u-boot,dm-pre-reloc;
		compatible = "fixed-clock";
		#clock-cells = <0x0>;
		clock-frequency = <0x19bfcc0>;
		phandle = <0x9>;
	};

	dp_aclk {
		compatible = "fixed-clock";
		#clock-cells = <0x0>;
		clock-frequency = <0x5f5e100>;
		clock-accuracy = <0x64>;
		phandle = <0x24>;
	};

	aliases {
		i2c0 = "/axi/i2c@ff020000";
		i2c1 = "/axi/i2c@ff030000";
		mmc0 = "/axi/mmc@ff160000";
		mmc1 = "/axi/mmc@ff170000";
		nvmem0 = "/axi/i2c@ff030000/eeprom@50";
		nvmem1 = "/axi/i2c@ff030000/eeprom@51";
		rtc0 = "/axi/rtc@ffa60000";
		serial0 = "/axi/serial@ff000000";
		serial1 = "/axi/serial@ff010000";
		serial2 = "/dcc";
		spi0 = "/axi/spi@ff0f0000";
		spi1 = "/axi/spi@ff040000";
		spi2 = "/axi/spi@ff050000";
		usb0 = "/axi/usb0@ff9d0000";
		usb1 = "/axi/usb1@ff9e0000";
	};

	chosen {
		bootargs = "earlycon";
		stdout-path = "serial1:115200n8";
	};

	memory@0 {
		device_type = "memory";
		reg = <0x0 0x0 0x0 0x80000000 0x8 0x0 0x0 0x80000000>;
	};

	gpio-keys {
		compatible = "gpio-keys";
		autorepeat;

		fwuen {
			label = "fwuen";
			gpios = <0x14 0xc 0x1>;
			linux,code = <0x100>;
			wakeup-source;
			autorepeat;
		};
	};

	leds {
		compatible = "gpio-leds";

		ds35-led {
			label = "heartbeat";
			gpios = <0x14 0x7 0x0>;
			linux,default-trigger = "heartbeat";
		};

		ds36-led {
			label = "vbus_det";
			gpios = <0x14 0x8 0x0>;
			default-state = "on";
		};
	};

	ams {
		compatible = "iio-hwmon";
		io-channels = <0x28 0x0 0x28 0x1 0x28 0x2 0x28 0x3 0x28 0x4 0x28 0x5 0x28 0x6 0x28 0x7 0x28 0x8 0x28 0x9 0x28 0xa 0x28 0xb 0x28 0xc 0x28 0xd 0x28 0xe 0x28 0xf 0x28 0x10 0x28 0x11 0x28 0x12 0x28 0x13 0x28 0x14 0x28 0x15 0x28 0x16 0x28 0x17 0x28 0x18 0x28 0x19 0x28 0x1a 0x28 0x1b 0x28 0x1c 0x28 0x1d>;
	};

	pwm-fan {
		compatible = "pwm-fan";
		status = "okay";
		pwms = <0x29 0x2 0x9c40 0x0>;
	};

	amba_pl@0 {
		#address-cells = <0x2>;
		#size-cells = <0x2>;
		compatible = "simple-bus";
		ranges;
		phandle = <0x90>;
	};

	ina260-u14 {
		compatible = "iio-hwmon";
		io-channels = <0x2a 0x0 0x2a 0x1 0x2a 0x2>;
	};

	clock0 {
		compatible = "fixed-clock";
		#clock-cells = <0x0>;
		clock-frequency = <0x7735940>;
		phandle = <0x19>;
	};

	clock1 {
		compatible = "fixed-clock";
		#clock-cells = <0x0>;
		clock-frequency = <0x19bfcc0>;
		phandle = <0x1a>;
	};

	clock2 {
		compatible = "fixed-clock";
		#clock-cells = <0x0>;
		clock-frequency = <0x18cba80>;
		phandle = <0x1b>;
	};

	clock3 {
		compatible = "fixed-clock";
		#clock-cells = <0x0>;
		clock-frequency = <0x9502f90>;
		phandle = <0x91>;
	};

	clock4 {
		compatible = "fixed-clock";
		#clock-cells = <0x0>;
		clock-frequency = <0x17d7840>;
		phandle = <0x92>;
	};

	clock5 {
		compatible = "fixed-clock";
		#clock-cells = <0x0>;
		clock-frequency = <0x17d7840>;
		phandle = <0x93>;
	};

	__symbols__ {
		cpu0 = "/cpus/cpu@0";
		cpu1 = "/cpus/cpu@1";
		cpu2 = "/cpus/cpu@2";
		cpu3 = "/cpus/cpu@3";
		CPU_SLEEP_0 = "/cpus/idle-states/cpu-sleep-0";
		cpu_opp_table = "/opp-table-cpu";
		zynqmp_ipi = "/zynqmp_ipi";
		ipi_mailbox_pmu1 = "/zynqmp_ipi/mailbox@ff990400";
		dcc = "/dcc";
		zynqmp_firmware = "/firmware/zynqmp-firmware";
		zynqmp_power = "/firmware/zynqmp-firmware/zynqmp-power";
		soc_revision = "/firmware/zynqmp-firmware/nvmem_firmware/soc_revision@0";
		efuse_dna = "/firmware/zynqmp-firmware/nvmem_firmware/efuse_dna@c";
		efuse_usr0 = "/firmware/zynqmp-firmware/nvmem_firmware/efuse_usr0@20";
		efuse_usr1 = "/firmware/zynqmp-firmware/nvmem_firmware/efuse_usr1@24";
		efuse_usr2 = "/firmware/zynqmp-firmware/nvmem_firmware/efuse_usr2@28";
		efuse_usr3 = "/firmware/zynqmp-firmware/nvmem_firmware/efuse_usr3@2c";
		efuse_usr4 = "/firmware/zynqmp-firmware/nvmem_firmware/efuse_usr4@30";
		efuse_usr5 = "/firmware/zynqmp-firmware/nvmem_firmware/efuse_usr5@34";
		efuse_usr6 = "/firmware/zynqmp-firmware/nvmem_firmware/efuse_usr6@38";
		efuse_usr7 = "/firmware/zynqmp-firmware/nvmem_firmware/efuse_usr7@3c";
		efuse_miscusr = "/firmware/zynqmp-firmware/nvmem_firmware/efuse_miscusr@40";
		efuse_chash = "/firmware/zynqmp-firmware/nvmem_firmware/efuse_chash@50";
		efuse_pufmisc = "/firmware/zynqmp-firmware/nvmem_firmware/efuse_pufmisc@54";
		efuse_sec = "/firmware/zynqmp-firmware/nvmem_firmware/efuse_sec@58";
		efuse_spkid = "/firmware/zynqmp-firmware/nvmem_firmware/efuse_spkid@5c";
		efuse_ppk0hash = "/firmware/zynqmp-firmware/nvmem_firmware/efuse_ppk0hash@a0";
		efuse_ppk1hash = "/firmware/zynqmp-firmware/nvmem_firmware/efuse_ppk1hash@d0";
		zynqmp_pcap = "/firmware/zynqmp-firmware/pcap";
		xlnx_aes = "/firmware/zynqmp-firmware/zynqmp-aes";
		zynqmp_reset = "/firmware/zynqmp-firmware/reset-controller";
		pinctrl0 = "/firmware/zynqmp-firmware/pinctrl";
		pinctrl_sdhci0_default = "/firmware/zynqmp-firmware/pinctrl/sdhci0-default";
		pinctrl_uart1_default = "/firmware/zynqmp-firmware/pinctrl/uart1-default";
		pinctrl_i2c1_default = "/firmware/zynqmp-firmware/pinctrl/i2c1-default";
		pinctrl_i2c1_gpio = "/firmware/zynqmp-firmware/pinctrl/i2c1-gpio";
		pinctrl_gem1_default = "/firmware/zynqmp-firmware/pinctrl/gem1-default";
		pinctrl_usb0_default = "/firmware/zynqmp-firmware/pinctrl/usb0-default";
		pinctrl_usb1_default = "/firmware/zynqmp-firmware/pinctrl/usb1-default";
		xlnx_keccak_384 = "/firmware/zynqmp-firmware/sha384";
		xlnx_rsa = "/firmware/zynqmp-firmware/zynqmp-rsa";
		modepin_gpio = "/firmware/zynqmp-firmware/gpio";
		zynqmp_clk = "/firmware/zynqmp-firmware/clock-controller";
		fpga_full = "/fpga-full";
		amba = "/axi";
		can0 = "/axi/can@ff060000";
		can1 = "/axi/can@ff070000";
		cci = "/axi/cci@fd6e0000";
		fpd_dma_chan1 = "/axi/dma-controller@fd500000";
		fpd_dma_chan2 = "/axi/dma-controller@fd510000";
		fpd_dma_chan3 = "/axi/dma-controller@fd520000";
		fpd_dma_chan4 = "/axi/dma-controller@fd530000";
		fpd_dma_chan5 = "/axi/dma-controller@fd540000";
		fpd_dma_chan6 = "/axi/dma-controller@fd550000";
		fpd_dma_chan7 = "/axi/dma-controller@fd560000";
		fpd_dma_chan8 = "/axi/dma-controller@fd570000";
		gic = "/axi/interrupt-controller@f9010000";
		gpu = "/axi/gpu@fd4b0000";
		lpd_dma_chan1 = "/axi/dma-controller@ffa80000";
		lpd_dma_chan2 = "/axi/dma-controller@ffa90000";
		lpd_dma_chan3 = "/axi/dma-controller@ffaa0000";
		lpd_dma_chan4 = "/axi/dma-controller@ffab0000";
		lpd_dma_chan5 = "/axi/dma-controller@ffac0000";
		lpd_dma_chan6 = "/axi/dma-controller@ffad0000";
		lpd_dma_chan7 = "/axi/dma-controller@ffae0000";
		lpd_dma_chan8 = "/axi/dma-controller@ffaf0000";
		mc = "/axi/memory-controller@fd070000";
		nand0 = "/axi/nand-controller@ff100000";
		gem0 = "/axi/ethernet@ff0b0000";
		gem1 = "/axi/ethernet@ff0c0000";
		mdio = "/axi/ethernet@ff0c0000/mdio";
		phy0 = "/axi/ethernet@ff0c0000/mdio/ethernet-phy@4";
		phy1 = "/axi/ethernet@ff0c0000/mdio/ethernet-phy@8";
		gem2 = "/axi/ethernet@ff0d0000";
		gem3 = "/axi/ethernet@ff0e0000";
		gpio = "/axi/gpio@ff0a0000";
		i2c0 = "/axi/i2c@ff020000";
		i2c1 = "/axi/i2c@ff030000";
		eeprom = "/axi/i2c@ff030000/eeprom@50";
		eeprom_cc = "/axi/i2c@ff030000/eeprom@51";
		da9131 = "/axi/i2c@ff030000/pmic@33";
		da9131_buck1 = "/axi/i2c@ff030000/pmic@33/regulators/buck1";
		da9131_buck2 = "/axi/i2c@ff030000/pmic@33/regulators/buck2";
		da9130 = "/axi/i2c@ff030000/pmic@32";
		da9130_buck1 = "/axi/i2c@ff030000/pmic@32/regulators/buck1";
		u14 = "/axi/i2c@ff030000/ina260@40";
		slg7xl45106 = "/axi/i2c@ff030000/gpio@11";
		usbhub_i2c0 = "/axi/i2c@ff030000/i2c-mux@74/i2c@0";
		usbhub_i2c1 = "/axi/i2c@ff030000/i2c-mux@74/i2c@1";
		ocm = "/axi/memory-controller@ff960000";
		perf_monitor_ocm = "/axi/perf-monitor@ffa00000";
		perf_monitor_ddr = "/axi/perf-monitor@fd0b0000";
		perf_monitor_cci = "/axi/perf-monitor@fd490000";
		perf_monitor_lpd = "/axi/perf-monitor@ffa10000";
		pcie = "/axi/pcie@fd0e0000";
		pcie_intc = "/axi/pcie@fd0e0000/legacy-interrupt-controller";
		qspi = "/axi/spi@ff0f0000";
		psgtr = "/axi/phy@fd400000";
		rtc = "/axi/rtc@ffa60000";
		sata = "/axi/ahci@fd0c0000";
		sdhci0 = "/axi/mmc@ff160000";
		sdhci1 = "/axi/mmc@ff170000";
		smmu = "/axi/iommu@fd800000";
		spi0 = "/axi/spi@ff040000";
		spi1 = "/axi/spi@ff050000";
		ttc0 = "/axi/timer@ff110000";
		ttc1 = "/axi/timer@ff120000";
		ttc2 = "/axi/timer@ff130000";
		ttc3 = "/axi/timer@ff140000";
		uart0 = "/axi/serial@ff000000";
		uart1 = "/axi/serial@ff010000";
		usb0 = "/axi/usb0@ff9d0000";
		dwc3_0 = "/axi/usb0@ff9d0000/usb@fe200000";
		usbhub0 = "/axi/usb0@ff9d0000/usb-hub";
		usb2244 = "/axi/usb0@ff9d0000/usb-sd";
		usb1 = "/axi/usb1@ff9e0000";
		dwc3_1 = "/axi/usb1@ff9e0000/usb@fe300000";
		usbhub1 = "/axi/usb1@ff9e0000/usb-hub";
		watchdog0 = "/axi/watchdog@fd4d0000";
		lpd_watchdog = "/axi/watchdog@ff150000";
		xilinx_ams = "/axi/ams@ffa50000";
		ams_ps = "/axi/ams@ffa50000/ams_ps@ffa50800";
		ams_pl = "/axi/ams@ffa50000/ams_pl@ffa50c00";
		zynqmp_dpdma = "/axi/dma-controller@fd4c0000";
		zynqmp_dpaud_setting = "/axi/dp_aud@fd4ac000";
		zynqmp_dpsub = "/axi/display@fd4a0000";
		zynqmp_dp_snd_codec0 = "/axi/display@fd4a0000/zynqmp_dp_snd_codec0";
		zynqmp_dp_snd_pcm0 = "/axi/display@fd4a0000/zynqmp_dp_snd_pcm0";
		zynqmp_dp_snd_pcm1 = "/axi/display@fd4a0000/zynqmp_dp_snd_pcm1";
		zynqmp_dp_snd_card0 = "/axi/display@fd4a0000/zynqmp_dp_snd_card";
		fclk0 = "/fclk0";
		fclk1 = "/fclk1";
		fclk2 = "/fclk2";
		fclk3 = "/fclk3";
		pss_ref_clk = "/pss_ref_clk";
		video_clk = "/video_clk";
		pss_alt_ref_clk = "/pss_alt_ref_clk";
		gt_crx_ref_clk = "/gt_crx_ref_clk";
		aux_ref_clk = "/aux_ref_clk";
		dp_aclk = "/dp_aclk";
		amba_pl = "/amba_pl@0";
		clk_125 = "/clock0";
		clk_27 = "/clock1";
		clk_26 = "/clock2";
		clk_156 = "/clock3";
		clk_25_0 = "/clock4";
		clk_25_1 = "/clock5";
	};
};
